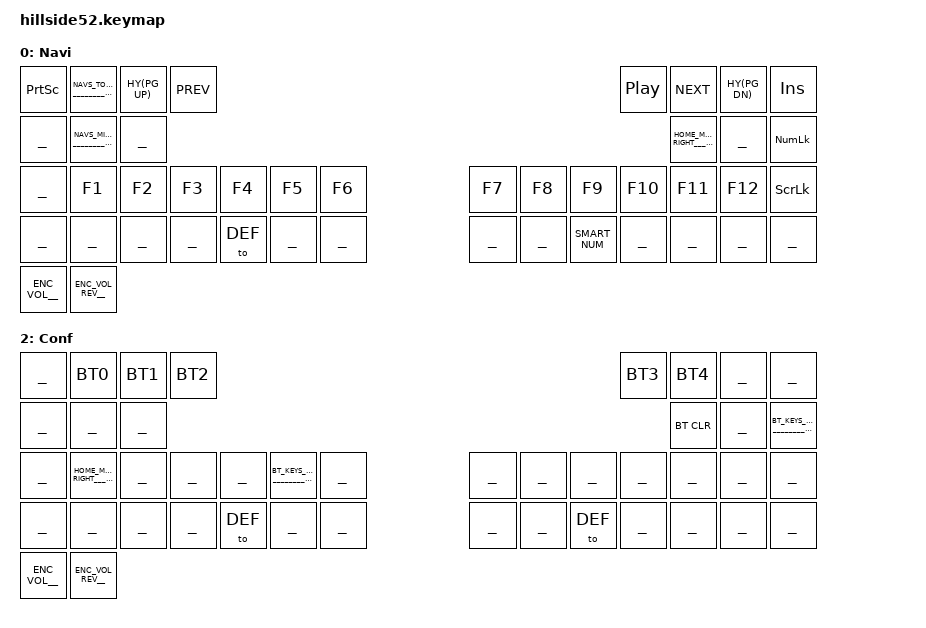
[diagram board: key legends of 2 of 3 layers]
// Copyright 2023 SpaceRock Media LLC

/*
  ╭────────────────────────╮               ╭────────────────────────╮
  │  0   1   2   3   4   5 │               │  6   7   8   9  10  11 │
  │ 12  13  14  15  16  17 ╰──╮         ╭──╯ 18  19  20  21  22  23 │
  │ 24  25  26  27  28  29  30╰────┬────╯31  32  33  34  35  36  37 │
  │ 38  39  40      41  42  43  44 │ 45  46  47  48      49  50  51 │
  ╰────────────────────────────────┴────────────────────────────────╯
 ╭─────────────────────────╮               ╭─────────────────────────╮
 │ LT5 LT4 LT3 LT2 LT1 LT0 │               │ RT0 RT1 RT2 RT3 RT4 RT5 │
 │ LM5 LM4 LM3 LM2 LM1 LM0 ╰──╮         ╭──╯ RM0 RM1 RM2 RM3 RM4 RM5 │
 │ LB5 LB4 LB3 LB2 LB1 LB0 LH4╰────┬────╯RH4 RB0 RB1 RB2 RB3 RB4 RB5 │
 │ LP2 LP1 LP0╭───╮LH3 LH2 LH1 LH0 │ RH0 RH1 RH2 RH3╭───╮RP0 RP1 RP2 │
 ╰────────────╯   ╰────────────────┴────────────────╯   ╰────────────╯
 T : Top
 M : Middle
 B : Bottom
 H : Hand
 P : Palm
*/

#include <behaviors.dtsi>
#include <dt-bindings/zmk/keys.h>
#include <dt-bindings/zmk/bt.h>
#include <dt-bindings/zmk/ext_power.h>
#include <dt-bindings/zmk/outputs.h>
#include <dt-bindings/zmk/rgb.h>

#include "../lib/zmk-helpers/keypos_def/keypos_52keys_hillside.h"
#include "../lib/zmk-helpers/helper.h"

#include "../spacerock/spacerock.dtsi"

#define BASE_LAYER_hillside(name, \
    __________________________LT__________________________, __________________________RT__________________________, \
    __________________________LM__________________________, __________________________RM__________________________, \
    __________________________LB__________________________, __________________________RB__________________________ \
) ZMK_LAYER(name, \
    &kp TAB    __________________________LT__________________________                                               __________________________RT__________________________ &kp C_PP  \
    HT_CTL_ESC __________________________LM__________________________                                               __________________________RM__________________________ &kp C_VOL_UP \
    &sk LGUI   __________________________LB__________________________ &kp HYP                            &kp MEH    __________________________RB__________________________ &kp RGUI \
    &sk LALT   &kp MEH &sk LGUI       &sk LCTRL   HT_TOG_NAV HT_MEH_SPC &sk LSHFT    &kp RSHFT  HT_MEH_ENT SMART_NUM  &sk RCTRL         &sk RGUI  &kp HYP    &kp C_MUTE \
    , __ENC_VOL__ __ENC_VOL_REV__ \
)

BASE_LAYER_hillside(Qwerty,
    ______________________QWERTY__LT______________________, ______________________QWERTY__RT______________________,
    ______________________QWERTY__LM______________________, ______________________QWERTY__RM______________________,
    ______________________QWERTY__LB______________________, ______________________QWERTY__RB______________________
)

BASE_LAYER_hillside(Colemak,
    ____________________COLEMAK_DH__LT____________________, ____________________COLEMAK_DH__RT____________________,
    ____________________COLEMAK_DH__LM____________________, ____________________COLEMAK_DH__RM____________________,
    ____________________COLEMAK_DH__LB____________________, ____________________COLEMAK_DH__RB____________________
)

#define HY_PG_UP &kp HY(PG_UP)
#define HY_PG_DN &kp HY(PG_DN)
ZMK_LAYER(Navi,
// ╭──────────┬──────────┬──────────┬──────────┬──────────┬──────────╮                                             ╭──────────┬──────────┬──────────┬──────────┬──────────┬──────────╮
    &kp PSCRN  _______________________NAVS_TOP_______________________                                               HY_PG_UP   &kp C_PREV &kp C_PP   &kp C_NEXT HY_PG_DN   &kp INS
// ├──────────┼──────────┼──────────┼──────────┼──────────┼──────────┤                                             ├──────────┼──────────┼──────────┼──────────┼──────────┼──────────┤
    ___        _______________________NAVS_MID_______________________                                               ___        ______HOME_MODS__GAC_RIGHT______ ___        &kp KP_NLCK
// ├──────────┼──────────┼──────────┼──────────┼──────────┼──────────┤──────────╮                       ╭──────────├──────────┼──────────┼──────────┼──────────┼──────────┼──────────┤
    ___        &kp F1     &kp F2     &kp F3     &kp F4     &kp F5     &kp F6                             &kp F7     &kp F8     &kp F9     &kp F10    &kp F11     &kp F12   &kp SLCK
// ╰──────────┴──────────┴──────────┴──────────┴──────────┴──────────╯──────────┴──────────╮ ╭──────────┴──────────╰──────────┴──────────┴──────────┴──────────┴──────────┴──────────╯
    ___        ___        ___                   ___        &to DEF ___        ___          ___        ___        SMART_NUM  ___                   ___        ___        ___
// ╰──────────┴──────────┴──────────╯          ╰──────────┴──────────┴──────────┴──────────╯ ╰──────────┴──────────┴──────────┴──────────╯          ╰──────────┴──────────┴──────────╯
    , __ENC_VOL__ __ENC_VOL_REV__
)

ZMK_LAYER(Nums,
// ╭──────────┬──────────┬──────────┬──────────┬──────────┬──────────╮                                             ╭──────────┬──────────┬──────────┬──────────┬──────────┬──────────╮
    ___        ___        ___        ___        ___        ___                                                      _______________________NUMS_TOP_______________________ &kp BSPC
// ├──────────┼──────────┼──────────┼──────────┼──────────┼──────────┤                                             ├──────────┼──────────┼──────────┼──────────┼──────────┼──────────┤
    ___        ___        _________HOME_MODS__GAC_________ ___                                                      _______________________NUMS_MID_______________________ &kp EQUAL
// ├──────────┼──────────┼──────────┼──────────┼──────────┼──────────┤──────────╮                       ╭──────────├──────────┼──────────┼──────────┼──────────┼──────────┼──────────┤
    ___        ___        ___        ___        ___        ___        ___                                ___        _______________________NUMS_BOT_______________________ &kp COMMA
// ╰──────────┴──────────┴──────────┴──────────┴──────────┴──────────╯──────────┴──────────╮ ╭──────────┴──────────╰──────────┴──────────┴──────────┴──────────┴──────────┴──────────╯
    ___        ___        ___                   ___        &to DEF &kp UNDER  ___          ___        ___        &to SYM ___                   ___        ___        ___
// ╰──────────┴──────────┴──────────╯          ╰──────────┴──────────┴──────────┴──────────╯ ╰──────────┴──────────┴──────────┴──────────╯          ╰──────────┴──────────┴──────────╯
    , __ENC_VOL__ __ENC_VOL_REV__
)

ZMK_LAYER(Conf,
// ╭──────────┬──────────┬──────────┬──────────┬──────────┬──────────╮                                             ╭──────────┬──────────┬──────────┬──────────┬──────────┬──────────╮
    ___        BT0        BT1        BT2        BT3        BT4                                                      ___        ___        ___        ___        ___        &bt BT_CLR
// ├──────────┼──────────┼──────────┼──────────┼──────────┼──────────┤                                             ├──────────┼──────────┼──────────┼──────────┼──────────┼──────────┤
    ___        ______________________BT_KEYS_UP______________________                                               ___        ______HOME_MODS__GAC_RIGHT______ ___        ___
// ├──────────┼──────────┼──────────┼──────────┼──────────┼──────────┤──────────╮                       ╭──────────├──────────┼──────────┼──────────┼──────────┼──────────┼──────────┤
    ___        ______________________BT_KEYS_DN______________________  ___                                ___        ___        ___        ___        ___        ___        ___
// ╰──────────┴──────────┴──────────┴──────────┴──────────┴──────────╯──────────┴──────────╮ ╭──────────┴──────────╰──────────┴──────────┴──────────┴──────────┴──────────┴──────────╯
    ___        ___        ___                   ___        &to DEF &kp UNDER  ___          ___        ___        &to DEF ___                   ___        ___        ___
// ╰──────────┴──────────┴──────────╯          ╰──────────┴──────────┴──────────┴──────────╯ ╰──────────┴──────────┴──────────┴──────────╯          ╰──────────┴──────────┴──────────╯
    , __ENC_VOL__ __ENC_VOL_REV__
)
